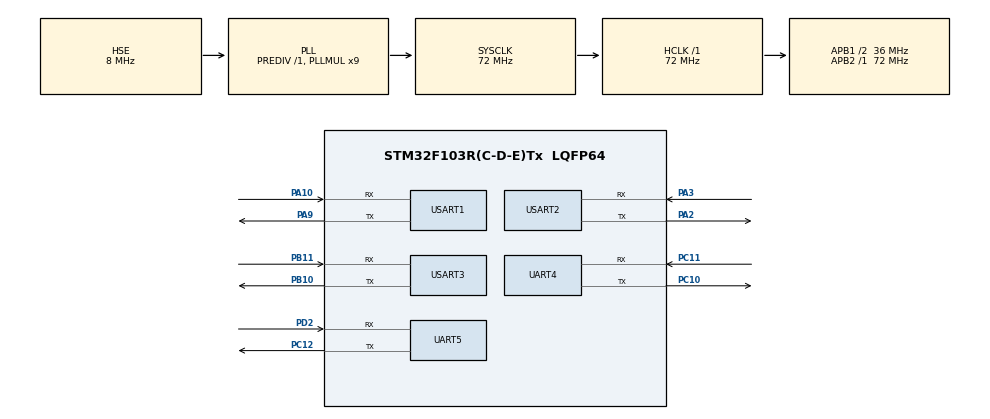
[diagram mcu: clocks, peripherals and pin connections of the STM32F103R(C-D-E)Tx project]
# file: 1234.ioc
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Dma.Request0=UART4_RX
Dma.UART4_RX.0.Direction=DMA_PERIPH_TO_MEMORY
Dma.UART4_RX.0.Instance=DMA2_Channel3
Dma.UART4_RX.0.MemDataAlignment=DMA_MDATAALIGN_BYTE
Dma.UART4_RX.0.MemInc=DMA_MINC_ENABLE
Dma.UART4_RX.0.Mode=DMA_NORMAL
Dma.UART4_RX.0.PeriphDataAlignment=DMA_PDATAALIGN_BYTE
Dma.UART4_RX.0.PeriphInc=DMA_PINC_DISABLE
Dma.UART4_RX.0.Priority=DMA_PRIORITY_LOW
Mcu.Family=STM32F1
Mcu.Name=STM32F103R(C-D-E)Tx
Mcu.Package=LQFP64
NVIC.DMA2_Channel3_IRQn=true\:0\:0\:false\:false\:true\:false\:true\:true
NVIC.PriorityGroup=NVIC_PRIORITYGROUP_4
NVIC.TIM6_IRQn=true\:0\:0\:false\:false\:true\:true\:true\:true
NVIC.UART4_IRQn=true\:0\:0\:false\:false\:true\:true\:true\:true
NVIC.UART5_IRQn=true\:0\:0\:false\:false\:true\:true\:true\:true
NVIC.USART1_IRQn=true\:0\:0\:false\:false\:true\:true\:true\:true
NVIC.USART2_IRQn=true\:0\:0\:false\:false\:true\:true\:true\:true
NVIC.USART3_IRQn=true\:0\:0\:false\:false\:true\:true\:true\:true
PA10.Mode=Asynchronous
PA10.Signal=USART1_RX
PA13.Mode=Serial_Wire
PA13.Signal=SYS_JTMS-SWDIO
PA14.Mode=Serial_Wire
PA14.Signal=SYS_JTCK-SWCLK
PA2.Mode=Asynchronous
PA2.Signal=USART2_TX
PA3.Mode=Asynchronous
PA3.Signal=USART2_RX
PA9.Mode=Asynchronous
PA9.Signal=USART1_TX
PB10.Mode=Asynchronous
PB10.Signal=USART3_TX
PB11.Mode=Asynchronous
PB11.Signal=USART3_RX
PC10.Mode=Asynchronous
PC10.Signal=UART4_TX
PC11.Mode=Asynchronous
PC11.Signal=UART4_RX
PC12.Mode=Asynchronous
PC12.Signal=UART5_TX
PD0-OSC_IN.Mode=HSE-External-Oscillator
PD0-OSC_IN.Signal=RCC_OSC_IN
PD1-OSC_OUT.Mode=HSE-External-Oscillator
PD1-OSC_OUT.Signal=RCC_OSC_OUT
PD2.Mode=Asynchronous
PD2.Signal=UART5_RX
ProjectManager.HeapSize=0x200
ProjectManager.StackSize=0x400
ProjectManager.TargetToolchain=MDK-ARM V5.32
RCC.AHBFreq_Value=72000000
RCC.APB1CLKDivider=RCC_HCLK_DIV2
RCC.APB1Freq_Value=36000000
RCC.APB1TimFreq_Value=72000000
RCC.APB2Freq_Value=72000000
RCC.APB2TimFreq_Value=72000000
RCC.HCLKFreq_Value=72000000
RCC.PLLMUL=RCC_PLL_MUL9
RCC.PLLSourceVirtual=RCC_PLLSOURCE_HSE
RCC.SYSCLKFreq_VALUE=72000000
RCC.SYSCLKSource=RCC_SYSCLKSOURCE_PLLCLK
RCC.USBFreq_Value=72000000
UART4.VirtualMode=Asynchronous
UART5.VirtualMode=Asynchronous
USART1.VirtualMode=VM_ASYNC
USART2.VirtualMode=VM_ASYNC
USART3.VirtualMode=VM_ASYNC
VP_TIM6_VS_ClockSourceINT.Mode=Enable_Timer
board=custom

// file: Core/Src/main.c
/* USER CODE BEGIN Header */
/**
  ******************************************************************************
  * @file           : main.c
  * @brief          : Main program body
  ******************************************************************************
  * @attention
  *
  * Copyright (c) 2023 STMicroelectronics.
  * All rights reserved.
  *
  * This software is licensed under terms that can be found in the LICENSE file
  * in the root directory of this software component.
  * If no LICENSE file comes with this software, it is provided AS-IS.
  *
  ******************************************************************************
  */
/* USER CODE END Header */
#include "main.h"
#include "dma.h"
#include "tim.h"
#include "usart.h"
#include "gpio.h"
#include "vision.h"
#include "laser.h"
#include "servo.h"
#include "pid.h"

void SystemClock_Config(void);

/* USER CODE BEGIN 0 */
#define SPPED 500
#define MS SPPED+100
/* USER CODE END 0 */

int main(void)
{

  /* MCU Configuration--------------------------------------------------------*/

  /* Reset of all peripherals, Initializes the Flash interface and the Systick. */
  HAL_Init();

  /* Configure the system clock */
  SystemClock_Config();

  /* Initialize all configured peripherals */
  MX_GPIO_Init();
  MX_DMA_Init();
  MX_TIM6_Init();
  MX_UART4_Init();
  MX_UART5_Init();
  MX_USART1_UART_Init();
  MX_USART2_UART_Init();
  MX_USART3_UART_Init();
	vision_receive_init();
  /* USER CODE BEGIN 2 */
 // HAL_UART_Receive_DMA(&huart1, (uint8_t *)rx_buffer, RX_BUFFER_SIZE);
  /* USER CODE END 2 */
   Servo_Init();
	 PID_init();
 	 HAL_Delay(2000);
	 //初始位置设置

	 OUT_servo_motor_angel();
	 SendCMD(0x03,2000,0x00,bastic_servo.now_angle,0x01,one_servo.now_angle,0x02,two_servo.now_angle,0x03,W_servo.now_angle);
	 HAL_Delay(2000+100);
	 Sendone(0x03,SPPED,0x05,50);
	 HAL_Delay(MS);
	 Sendone(0x03,SPPED,0x04,113);
	 HAL_Delay(MS);
//	 one_servo.temp_angle = data2angel(125);
//	 two_servo.temp_angle = data2angel(-125);
//	 W_servo.temp_angle = data2angel(0);
//	 bastic_servo.temp_angle = data2angel(90);
//	 OUT_servo_motor_angel();
//	 SendCMD(0x03,SPPED,0x00,bastic_servo.now_angle,0x01,one_servo.now_angle,0x02,two_servo.now_angle,0x03,W_servo.now_angle);
//	 HAL_Delay(MS);

//
//	 	 for(int i = 3;i>0;i--){
//		 if( Calculate_coordinate(15,30-3*i,0)){
//				 OUT_servo_motor_angel();
//				 SendCMD(0x03,SPPED,0x01,one_servo.now_angle,0x02,two_servo.now_angle,0x03,W_servo.now_angle);
//				HAL_Delay(MS);

//			 }
//   }
//		 for(int i = 1;i<=3;i++){
//		 if( Calculate_coordinate(15,30-3*i,0)){
//				 OUT_servo_motor_angel();
//				 SendCMD(0x03,SPPED,0x01,one_servo.now_angle,0x02,two_servo.now_angle,0x03,W_servo.now_angle);
//				HAL_Delay(MS);

//			 }
//   }

  /* Infinite loop */
  /* USER CODE BEGIN WHILE */
  while (1)
  {
		servo_control();
    /* USER CODE END WHILE */
//    printf(" %d   %d,%d\r\n",vision.ID,vision.data_X,vision.data_Y);
//		HAL_Delay(50);
  }
}

void SystemClock_Config(void)
{
  RCC_OscInitTypeDef RCC_OscInitStruct = {0};
  RCC_ClkInitTypeDef RCC_ClkInitStruct = {0};

  /** Initializes the RCC Oscillators according to the specified parameters
  * in the RCC_OscInitTypeDef structure.
  */
  RCC_OscInitStruct.OscillatorType = RCC_OSCILLATORTYPE_HSE;
  RCC_OscInitStruct.HSEState = RCC_HSE_ON;
  RCC_OscInitStruct.HSEPredivValue = RCC_HSE_PREDIV_DIV1;
  RCC_OscInitStruct.HSIState = RCC_HSI_ON;
  RCC_OscInitStruct.PLL.PLLState = RCC_PLL_ON;
  RCC_OscInitStruct.PLL.PLLSource = RCC_PLLSOURCE_HSE;
  RCC_OscInitStruct.PLL.PLLMUL = RCC_PLL_MUL9;
  if (HAL_RCC_OscConfig(&RCC_OscInitStruct) != HAL_OK)
  {
    Error_Handler();
  }

  /** Initializes the CPU, AHB and APB buses clocks
  */
  RCC_ClkInitStruct.ClockType = RCC_CLOCKTYPE_HCLK|RCC_CLOCKTYPE_SYSCLK
                              |RCC_CLOCKTYPE_PCLK1|RCC_CLOCKTYPE_PCLK2;
  RCC_ClkInitStruct.SYSCLKSource = RCC_SYSCLKSOURCE_PLLCLK;
  RCC_ClkInitStruct.AHBCLKDivider = RCC_SYSCLK_DIV1;
  RCC_ClkInitStruct.APB1CLKDivider = RCC_HCLK_DIV2;
  RCC_ClkInitStruct.APB2CLKDivider = RCC_HCLK_DIV1;

  if (HAL_RCC_ClockConfig(&RCC_ClkInitStruct, FLASH_LATENCY_2) != HAL_OK)
  {
    Error_Handler();
  }
}

void Error_Handler(void)
{
  __disable_irq();
  while (1)
  {
  }
}
